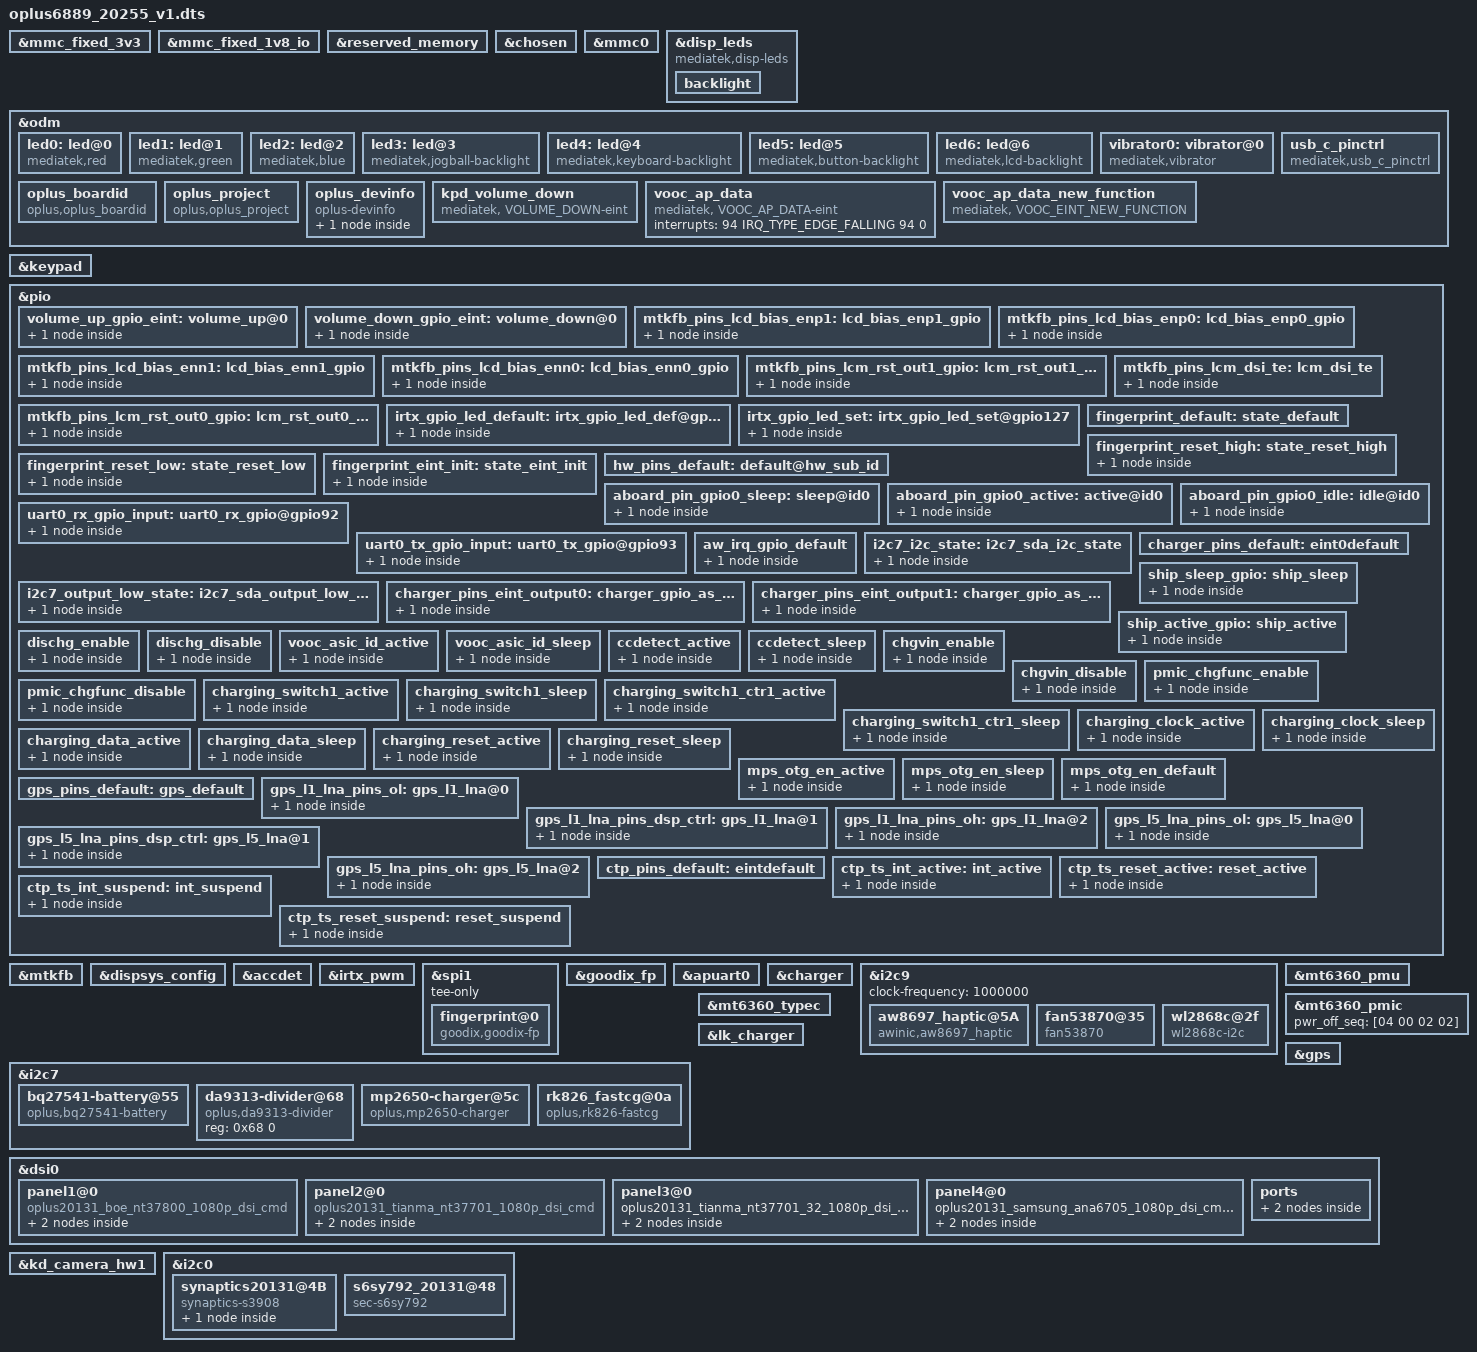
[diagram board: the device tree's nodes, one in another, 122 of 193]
// SPDX-License-Identifier: GPL-2.0
/*
 * Copyright (c) 2019 MediaTek Inc.
 *
 */
/dts-v1/;
/plugin/;
#include <dt-bindings/interrupt-controller/irq.h>
#include <dt-bindings/interrupt-controller/arm-gic.h>
#include <dt-bindings/spmi/spmi.h>
#include <dt-bindings/pinctrl/mt6885-pinfunc.h>

&mmc_fixed_3v3 {
	status = "okay";
	regulator-name = "mmc_power";
	regulator-min-microvolt = <3300000>;
	regulator-max-microvolt = <3300000>;
	enable-active-high;
	regulator-always-on;
};

&mmc_fixed_1v8_io {
	status = "okay";
	regulator-name = "mmc_io";
	regulator-min-microvolt = <1800000>;
	regulator-max-microvolt = <1800000>;
	enable-active-high;
	regulator-always-on;
};

&reserved_memory {
};

/* chosen */
&chosen {

	atag,videolfb-fb_base_l = <0x7e020000>;
	atag,videolfb-fb_base_h = <0x0>;
	atag,videolfb-islcmfound = <1>;
	atag,videolfb-islcm_inited = <0>;
	atag,videolfb-fps= <6000>;
	atag,videolfb-vramSize= <0x1be0000>;
	atag,videolfb-lcmname=
		"nt35595_fhd_dsi_cmd_truly_nt50358_drv";
};

&mmc0 {
	status = "okay";
	/* pinctrl-names = "default", "state_uhs"; */
	/* pinctrl-0 = <&mmc0_pins_default>; */
	/* pinctrl-1 = <&mmc0_pins_uhs>; */
	bus-width = <8>;
	max-frequency = <5000000>;
	cap-mmc-highspeed;
	no-sdio;
	no-sd;
	vmmc-supply = <&mmc_fixed_3v3>;
	vqmmc-supply = <&mmc_fixed_1v8_io>;
	non-removable;
};

&disp_leds {
	compatible = "mediatek,disp-leds";
	backlight {
		label = "lcd-backlight";
		max-brightness = <4095>;
		led-bits = <12>;
		trans-bits = <12>;
		default-state = "on";
	};
};

&odm {
	led0:led@0 {
		compatible = "mediatek,red";
		led_mode = <0>;
		data = <1>;
		pwm_config = <0 0 0 0 0>;
	};
	led1:led@1 {
		compatible = "mediatek,green";
		led_mode = <0>;
		data = <1>;
		pwm_config = <0 0 0 0 0>;
	};
	led2:led@2 {
		compatible = "mediatek,blue";
		led_mode = <0>;
		data = <1>;
		pwm_config = <0 0 0 0 0>;
	};
	led3:led@3 {
		compatible = "mediatek,jogball-backlight";
		led_mode = <0>;
		data = <1>;
		pwm_config = <0 0 0 0 0>;
	};
	led4:led@4 {
		compatible = "mediatek,keyboard-backlight";
		led_mode = <0>;
		data = <1>;
		pwm_config = <0 0 0 0 0>;
	};
	led5:led@5 {
		compatible = "mediatek,button-backlight";
		led_mode = <0>;
		data = <1>;
		pwm_config = <0 0 0 0 0>;
	};
	led6:led@6 {
		compatible = "mediatek,lcd-backlight";
		led_mode = <0>;
		data = <1>;
		pwm_config = <0 1 0 0 0>;
	};
	vibrator0:vibrator@0 {
		compatible = "mediatek,vibrator";
		vib_timer = <25>;
		vib_limit = <9>;
		vib_vol= <9>;
	};
	usb_c_pinctrl:usb_c_pinctrl {
		compatible = "mediatek,usb_c_pinctrl";
	};

	oplus_boardid:oplus_boardid {
		compatible = "oplus,oplus_boardid";
		oplus_boardid,dtsino="20255";//only one u32
		oplus_boardid,pcbmask="0x0004";//all mask 0xffff
	};

/*OPLUS_FEATURE_TP_BASIC oplus project start */
	oplus_project:oplus_project {
		compatible = "oplus,oplus_project";
	};
	oplus_devinfo:oplus_devinfo {
		compatible = "oplus-devinfo";
		pinctrl-names = "default", "aboard_gpio0_sleep", "aboard_gpio0_active", "aboard_gpio0_idle";
		pinctrl-0 = <&hw_pins_default>;
		pinctrl-1 = <&aboard_pin_gpio0_sleep>;
		pinctrl-2 = <&aboard_pin_gpio0_active>;
		pinctrl-3 = <&aboard_pin_gpio0_idle>;
		main-sub {
			use_tristate_gpio;
			compatible = "hw-match, main-sub";
			aboard-gpio0 = <&pio 132 0x00>;
			aboard-patterns = <1 1>;	/*0[high-resistance] 1[pull-down] 2[pull-up]*/
			/*main board*/
			match-projects = <20255 20257>;
		};
	};
/*OPLUS_FEATURE_TP_BASIC oplus project end */

//#ifdef OPLUS_FEATURE_TP_BASIC
        kpd_volume_down:kpd_volume_down {
                compatible = "mediatek, VOLUME_DOWN-eint";
                interrupt-parent = <&pio>;
                interrupts = <155 IRQ_TYPE_EDGE_FALLING 155 0>;
                debounce = <32000>;
                status = "okay";
        };
//#endif OPLUS_FEATURE_TP_BASIC

};
//#ifdef OPLUS_FEATURE_TP_BASIC
&keypad {
        keypad,volume-up        = <&pio 20 0x00>;
        keypad,volume-down      = <&pio 155 0x00>;
        pinctrl-names = "volume_up_as_int", "volume_down_as_int";
        pinctrl-0 = <&volume_up_gpio_eint>;
        pinctrl-1 = <&volume_down_gpio_eint>;
        status = "okay";
};

&pio {
        volume_up_gpio_eint:volume_up@0{
                pins_cmd_dat {
                        pinmux = <PINMUX_GPIO59__FUNC_GPIO59>;
                        slew-rate = <0>;  /*direction 0:in, 1:out*/
                        input-enable;
                };
        };

        volume_down_gpio_eint:volume_down@0{
                pins_cmd_dat {
                        pinmux = <PINMUX_GPIO155__FUNC_GPIO155>;
                        slew-rate = <0>;  /*direction 0:in, 1:out*/
                        input-enable;
                };
        };
};
//#endif OPLUS_FEATURE_TP_BASIC

/* DISPSYS GPIO standardization */
&pio {
	mtkfb_pins_lcd_bias_enp1: lcd_bias_enp1_gpio {
		pins_cmd_dat {
			pinmux = <PINMUX_GPIO28__FUNC_GPIO28>;
			slew-rate = <1>;
			output-high;
		};
	};

	mtkfb_pins_lcd_bias_enp0: lcd_bias_enp0_gpio {
		pins_cmd_dat {
			pinmux = <PINMUX_GPIO28__FUNC_GPIO28>;
			slew-rate = <1>;
			output-low;
		};
	};

	mtkfb_pins_lcd_bias_enn1: lcd_bias_enn1_gpio {
		pins_cmd_dat {
			pinmux = <PINMUX_GPIO29__FUNC_GPIO29>;
			slew-rate = <1>;
			output-high;
		};
	};

	mtkfb_pins_lcd_bias_enn0: lcd_bias_enn0_gpio {
		pins_cmd_dat {
			pinmux = <PINMUX_GPIO29__FUNC_GPIO29>;
			slew-rate = <1>;
			output-low;
		};
	};

	mtkfb_pins_lcm_rst_out1_gpio: lcm_rst_out1_gpio {
		pins_cmd_dat {
			pinmux = <PINMUX_GPIO42__FUNC_GPIO42>;
			slew-rate = <1>;
			output-high;
		};
	};

	mtkfb_pins_lcm_rst_out0_gpio: lcm_rst_out0_gpio {
		pins_cmd_dat {
			pinmux = <PINMUX_GPIO42__FUNC_GPIO42>;
			slew-rate = <1>;
			output-low;
		};
	};

	mtkfb_pins_lcm_dsi_te: lcm_dsi_te {
		pins_cmd_dat {
			pinmux = <PINMUX_GPIO41__FUNC_DSI_TE>;
		};
	};
};

&mtkfb {
	pinctrl-names = "lcd_bias_enp1_gpio", "lcd_bias_enp0_gpio",
		"lcd_bias_enn1_gpio", "lcd_bias_enn0_gpio",
		"lcm_rst_out1_gpio", "lcm_rst_out0_gpio",
		"mode_te_te";
	pinctrl-0 = <&mtkfb_pins_lcd_bias_enp1>;
	pinctrl-1 = <&mtkfb_pins_lcd_bias_enp0>;
	pinctrl-2 = <&mtkfb_pins_lcd_bias_enn1>;
	pinctrl-3 = <&mtkfb_pins_lcd_bias_enn0>;
	pinctrl-4 = <&mtkfb_pins_lcm_rst_out1_gpio>;
	pinctrl-5 = <&mtkfb_pins_lcm_rst_out0_gpio>;
	pinctrl-6 = <&mtkfb_pins_lcm_dsi_te>;
	status = "okay";
};

&dispsys_config {
	pinctrl-names =
		"lcm_rst_out1_gpio", "lcm_rst_out0_gpio",
		"mode_te_te";
	pinctrl-0 = <&mtkfb_pins_lcm_rst_out1_gpio>;
	pinctrl-1 = <&mtkfb_pins_lcm_rst_out0_gpio>;
	pinctrl-2 = <&mtkfb_pins_lcm_dsi_te>;
	status = "okay";

	helper-value = <0>, /*MTK_DRM_OPT_STAGE*/
		<1>, /*MTK_DRM_OPT_USE_CMDQ*/
		<1>, /*MTK_DRM_OPT_USE_M4U*/
		<0>, /*MTK_DRM_OPT_SODI_SUPPORT*/
		<1>, /*MTK_DRM_OPT_IDLE_MGR*/
		<0>, /*MTK_DRM_OPT_IDLEMGR_SWTCH_DECOUPLE*/
		<1>, /*MTK_DRM_OPT_IDLEMGR_BY_REPAINT*/
		<0>, /*MTK_DRM_OPT_IDLEMGR_ENTER_ULPS*/
		<0>, /*MTK_DRM_OPT_IDLEMGR_KEEP_LP11*/
		<0>, /*MTK_DRM_OPT_DYNAMIC_RDMA_GOLDEN_SETTING*/
		<1>, /*MTK_DRM_OPT_IDLEMGR_DISABLE_ROUTINE_IRQ*/
		<0>, /*MTK_DRM_OPT_MET_LOG*/
		<1>, /*MTK_DRM_OPT_USE_PQ*/
		<1>, /*MTK_DRM_OPT_ESD_CHECK_RECOVERY*/
		<1>, /*MTK_DRM_OPT_ESD_CHECK_SWITCH*/
		<1>, /*MTK_DRM_OPT_PRESENT_FENCE*/
		<0>, /*MTK_DRM_OPT_RDMA_UNDERFLOW_AEE*/
		<0>, /*MTK_DRM_OPT_DSI_UNDERRUN_AEE*/
		<1>, /*MTK_DRM_OPT_HRT*/
		<1>, /*MTK_DRM_OPT_HRT_MODE*/
		<0>, /*MTK_DRM_OPT_DELAYED_TRIGGER*/
		<1>, /*MTK_DRM_OPT_OVL_EXT_LAYER*/
		<0>, /*MTK_DRM_OPT_AOD*/
		<1>, /*MTK_DRM_OPT_RPO*/
		<0>, /*MTK_DRM_OPT_DUAL_PIPE*/
		<0>, /*MTK_DRM_OPT_DC_BY_HRT*/
		<1>, /*MTK_DRM_OPT_OVL_WCG*/
		<0>, /*MTK_DRM_OPT_OVL_SBCH*/
		<1>, /*MTK_DRM_OPT_COMMIT_NO_WAIT_VBLANK*/
		<0>, /*MTK_DRM_OPT_MET*/
		<0>, /*MTK_DRM_OPT_REG_PARSER_RAW_DUMP*/
		<0>, /*MTK_DRM_OPT_VP_PQ*/
		<0>, /*MTK_DRM_OPT_GAME_PQ*/
		<0>, /*MTK_DRM_OPT_MMPATH*/
		<1>, /*MTK_DRM_OPT_HBM*/
		<0>, /*MTK_DRM_OPT_VDS_PATH_SWITCH*/
		<0>, /*MTK_DRM_OPT_LAYER_REC*/
		<1>, /*MTK_DRM_OPT_CLEAR_LAYER*/
		<0>, /*MTK_DRM_OPT_SF_PF*/
		<1>, /*MTK_DRM_OPT_PRIM_DUAL_PIPE*/
		<1>; /*MTK_DRM_OPT_DYN_MIPI_CHANGE*/
};
/* DISPSYS GPIO standardization end */

/* accdet start */
&accdet {
	/* accdet micbias voltage: 0x09:2.85v 0x08:2.8v 0x07,
	 * 2.7v;0x05,2.5v;0x02,1.9v
	 */
	accdet-mic-vol = <8>;
	/* accdet pwm_width, pwm_thresh, fall_delay, rise_delay
	 * debounce0, debounce1, debounce3, debounce4
	 * eint pwm_width, eint pwm_thresh
	 * eint deb(debounce0, debounce1, debounce2, debounce3), inv_debounce
	 */
	headset-mode-setting = <0x500 0x500 1 0x1f0
				0x800 0x800 0x20 0x44
				0x4 0x1
				0x5 0x3 0x3 0x5 0xe>;
	accdet-plugout-debounce = <1>;
	/*1:ACC mode, 2:low cost without in bias, 6:low cost with in bias*/
	accdet-mic-mode = <2>;
	/*0--MD_MAX--UP_MAX--DW_MAX*/
	headset-three-key-threshold = <0 80 220 400>;
	headset-three-key-threshold-CDD = <0 121 192 600>;
	/*0--MD_MAX--VOICE_MAX--UP_MAX--DW_MAX*/
	headset-four-key-threshold = <0 58 121 192 400>;

	/* select VTH to 2v and 500k, use internal resitance */
	eint_use_ext_res = <0>;
	status = "okay";
};
/* accdet end */

/* IRTX GPIO Start */
&irtx_pwm {
	pinctrl-names = "irtx_gpio_led_default", "irtx_gpio_led_set";
	pinctrl-0 = <&irtx_gpio_led_default>;
	pinctrl-1 = <&irtx_gpio_led_set>;
	status = "okay";
};
&pio {
	/* IRTX GPIO Settings -Start */
	/* default: GPIO0, output, high */
	irtx_gpio_led_default:irtx_gpio_led_def@gpio127 {
		pins_cmd_dat {
			pinmux = <PINMUX_GPIO127__FUNC_GPIO127>;
			slew-rate = <1>;
			bias-disable;
			output-low;
			input-schmitt-enable = <0>;
		};
	};

	irtx_gpio_led_set:irtx_gpio_led_set@gpio127 {
		pins_cmd_dat {
			pinmux = <PINMUX_GPIO127__FUNC_PWM_3>;
			slew-rate = <1>;
			output-high;
		};
	};
}; /* IRTX GPIO Settings -End */

/* FINGERPRINT start */
&spi1 {
	#address-cells = <1>;
	#size-cells = <0>;
	tee-only;
	fingerprint@0 {
		compatible = "goodix,goodix-fp";
		reg = <0>;
		spi-max-frequency = <8000000>;
		netlink-event = <30>;
		vfp-supply = <&mt_pmic_vfp_ldo_reg>;
		power-type = <1>;
		status = "okay";
	};
};

&goodix_fp {
	pinctrl-names = "default", "reset_high", "reset_low", "eint_init";
	pinctrl-0 = <&fingerprint_default>;
	pinctrl-1 = <&fingerprint_reset_high>;
	pinctrl-2 = <&fingerprint_reset_low>;
	pinctrl-3 = <&fingerprint_eint_init>;
	interrupt-parent = <&pio>;
	interrupts = <15 IRQ_TYPE_EDGE_RISING 15 0>;
	status = "okay";
};

&pio {
	fingerprint_default: state_default {
	};
	fingerprint_reset_high: state_reset_high {
		pins_cmd_dat {
			pinmux = <PINMUX_GPIO14__FUNC_GPIO14>;
			slew-rate = <1>;
			output-high;
		};
	};
	fingerprint_reset_low: state_reset_low {
		pins_cmd_dat {
			pinmux = <PINMUX_GPIO14__FUNC_GPIO14>;
			slew-rate = <1>;
			output-low;
		};
	};
	fingerprint_eint_init: state_eint_init {
		pins_cmd_dat {
			pinmux = <PINMUX_GPIO15__FUNC_GPIO15>;
			slew-rate = <0>;
			bias-pull-up = <MTK_PUPD_SET_R1R0_10>;
			input-schmitt-enable;
		};
	};
};
/* FINGERPRINT end */
&pio {
    hw_pins_default:default@hw_sub_id {
    };

    aboard_pin_gpio0_sleep:sleep@id0 {
        pins_cmd_dat {
            pinmux = <PINMUX_GPIO132__FUNC_GPIO132>;
            slew-rate = <0>;
            bias-pull-down;
            input-enable;
        };
    };

    aboard_pin_gpio0_active:active@id0 {
        pins_cmd_dat {
            pinmux = <PINMUX_GPIO132__FUNC_GPIO132>;
            slew-rate = <0>;
            bias-pull-up;
            input-enable;
        };
    };

    aboard_pin_gpio0_idle:idle@id0 {
        pins_cmd_dat {
            pinmux = <PINMUX_GPIO132__FUNC_GPIO132>;
            slew-rate = <0>;
            bias-disable;
            input-enable;
        };
    };
};

&apuart0 {
	pinctrl-names = "uart0_rx_gpio","uart0_tx_gpio";
	pinctrl-0 = <&uart0_rx_gpio_input>;
	pinctrl-1 = <&uart0_tx_gpio_input>;
	status = "okay";
};

&pio {
	uart0_rx_gpio_input:uart0_rx_gpio@gpio92 {
		pins_cmd_dat {
			pinmux = <PINMUX_GPIO92__FUNC_GPIO92>;
			input-enable;
			slew-rate = <0>;
			bias-disable;
		};
	};
	uart0_tx_gpio_input:uart0_tx_gpio@gpio93 {
		pins_cmd_dat {
			pinmux = <PINMUX_GPIO93__FUNC_GPIO93>;
			input-enable;
			slew-rate = <0>;
			bias-disable;
		};
	};
};

/* 2020/07/30, zdr Add for oplus charge .*/
&charger {
	io-channels = <&auxadc 4>,
		<&auxadc 5>;
	io-channel-names = "auxadc4-usb_temp_v_l",
		"auxadc5-usb_temp_v_r";

	pinctrl-names = "default", "charger_gpio_as_output_low", "charger_gpio_as_output_high", "ship_sleep", "ship_active",
		"dischg_enable", "dischg_disable", "chgvin_enable", "chgvin_disable", "pmic_chgfunc_enable", "pmic_chgfunc_disable",
		"ccdetect_active","ccdetect_sleep";
	pinctrl-0 = <&charger_pins_default>;
	pinctrl-1 = <&charger_pins_eint_output0>;	//USB_ON -> USB_SWITCH:(UART && USB)
	pinctrl-2 = <&charger_pins_eint_output1>;
	pinctrl-3 = <&ship_sleep_gpio>;				//ship_mode
	pinctrl-4 = <&ship_active_gpio>;
	pinctrl-5 = <&dischg_enable>;				//usb_hightemp_port
	pinctrl-6 = <&dischg_disable>;
	pinctrl-7 = <&chgvin_enable>;					//EVB GPIO30 chgvin
	pinctrl-8 = <&chgvin_disable>;
	pinctrl-9 = <&pmic_chgfunc_enable>;				//EVB GPIO26 chg_enable
	pinctrl-10 = <&pmic_chgfunc_disable>;
	//pinctrl-5 = <&shortc_active_gpio>;
	pinctrl-11 = <&ccdetect_active>;
	pinctrl-12 = <&ccdetect_sleep>;
	qcom,hv_flashled_support;
	qcom,chargerid_support;
	qcom,smart_charging_screenoff;
	qcom,usbtemp_batttemp_gap = <18>;
	qcom,input_current_charger_ma = <2000>;
	qcom,pd_input_current_charger_ma = <2000>;
	qcom,qc_input_current_charger_ma = <2000>;
	qcom,input_current_usb_ma = <500>;

	qcom,input_current_led_ma = <1200>;
	qcom,input_current_led_ma_high = <1200>;
	qcom,input_current_led_ma_warm = <1500>;
	qcom,input_current_led_ma_normal = <2000>;
	qcom,led_warm_bat_decidegc = <350>;
	qcom,led_high_bat_decidegc = <370>;

	qcom,input_current_camera_ma = <1200>;
	qcom,input_current_cdp_ma = <1500>;

	qcom,input_current_vooc_led_ma_high = <1200>;
	qcom,input_current_vooc_led_ma_warm = <1800>;
	qcom,input_current_vooc_led_ma_normal = <3600>;
	qcom,input_current_vooc_ma_normal = <3600>;
	qcom,vooc_temp_bat_normal_decidegc = <350>;
	qcom,input_current_vooc_ma_warm = <3200>;
	qcom,vooc_temp_bat_warm_decidegc = <370>;
	qcom,input_current_vooc_ma_high = <2200>;
	qcom,vooc_temp_bat_hot_decidegc = <440>;

	qcom,charger_current_vooc_ma_normal = <1800>;

	qcom,chg_ctrl_by_calling;
	qcom,input_current_calling_ma = <1500>;

	qcom,overtemp_bat_decidegc = <350>;
	qcom,iterm_disabled = <0>;
	sw_full_count = <25>;
	qcom,iterm_ma = <118>;
	qcom,recharge-mv = <100>;
	qcom,batt_capacity_mah = <4250>;/*typical capacity*/

	qcom,removed_bat_decidegc = <190>;  /*<-19C*/

	qcom,cold_bat_decidegc = <20>;  /*-2C~0C*/
	qcom,temp_cold_vfloat_mv = <3980>;
	qcom,temp_cold_fastchg_current_ma = <300>;

	qcom,little_cold_bat_decidegc = <0>;    /*0C~5C*/
	qcom,temp_little_cold_vfloat_mv = <4435>;
	qcom,temp_little_cold_fastchg_current_ma_high = <1100>;
	qcom,temp_little_cold_fastchg_current_ma_low = <1100>;
	qcom,temp_little_cold_fastchg_current_ma = <920>;
	qcom,pd_temp_little_cold_fastchg_current_ma_high = <2000>;
	qcom,pd_temp_little_cold_fastchg_current_ma_low = <1400>;
	qcom,qc_temp_little_cold_fastchg_current_ma_high = <2000>;
	qcom,qc_temp_little_cold_fastchg_current_ma_low = <1400>;

	qcom,cool_bat_decidegc = <50>;  /*5C~12C*/
	qcom,temp_cool_vfloat_mv = <4435>;
	qcom,temp_cool_fastchg_current_ma_high = <1100>;
	qcom,temp_cool_fastchg_current_ma_low = <1100>;
	qcom,pd_temp_cool_fastchg_current_ma_high = <2000>;
	qcom,pd_temp_cool_fastchg_current_ma_low = <2000>;
	qcom,qc_temp_cool_fastchg_current_ma_high = <2000>;
	qcom,qc_temp_cool_fastchg_current_ma_low = <2000>;

	qcom,little_cool_bat_decidegc = <120>;  /*12C~16C*/
	qcom,temp_little_cool_vfloat_mv = <4435>;
	qcom,temp_little_cool_fastchg_current_ma = <1100>;
	qcom,pd_temp_little_cool_fastchg_current_ma = <2000>;
	qcom,qc_temp_little_cool_fastchg_current_ma = <2000>;

	qcom,normal_bat_decidegc = <160>;       /*16C~44C*/
	qcom,temp_normal_fastchg_current_ma = <2000>;
	qcom,temp_normal_vfloat_mv = <4435>;
	qcom,pd_temp_normal_fastchg_current_ma = <2000>;
	qcom,qc_temp_normal_fastchg_current_ma = <2000>;

	qcom,warm_bat_decidegc = <450>;         /*45C~53C*/ /*8pin Bat Vooc project need add 3 degree C*/
	qcom,temp_warm_vfloat_mv = <4130>;
	qcom,temp_warm_fastchg_current_ma = <600>;
	qcom,pd_temp_warm_fastchg_current_ma = <600>;
	qcom,qc_temp_warm_fastchg_current_ma = <600>;
	qcom,temp_warm_fastchg_current_ma_led_on = <250>;

	qcom,hot_bat_decidegc = <530>;

	qcom,non_standard_vfloat_mv = <3980>;
	qcom,non_standard_fastchg_current_ma = <512>;

	qcom,short_c_bat_cv_mv = <4330>;
	qcom,short_c_bat_vfloat_mv = <3800>;
	qcom,short_c_bat_fastchg_current_ma = <512>;

	qcom,cold_vfloat_sw_limit = <3930>;
	qcom,little_cold_vfloat_sw_limit = <4385>;
	qcom,cool_vfloat_sw_limit = <4385>;
	qcom,little_cool_vfloat_sw_limit = <4385>;
	qcom,normal_vfloat_sw_limit = <4385>;
	qcom,warm_vfloat_sw_limit = <4080>;
	qcom,non_standard_vfloat_sw_limit = <3930>;
	qcom,short_c_bat_vfloat_sw_limit = <3750>;

	qcom,max_chg_time_sec = <60480>;
	qcom,charger_hv_thr = <9900>;
	qcom,charger_recv_thr = <9500>;
	qcom,charger_lv_thr = <3400>;
	qcom,vbatt_full_thr = <4435>;
	qcom,vbatt_hv_thr = <4600>;
	qcom,vfloat_step_mv = <8>;
	qcom,non_standard_vfloat_over_sw_limit = <3990>;
	qcom,cold_vfloat_over_sw_limit = <3990>;
	qcom,little_cold_vfloat_over_sw_limit = <4445>;
	qcom,cool_vfloat_over_sw_limit = <4445>;
	qcom,little_cool_vfloat_over_sw_limit = <4445>;
	qcom,normal_vfloat_over_sw_limit = <4445>;
	qcom,warm_vfloat_over_sw_limit = <4140>;

	qcom,vbatt_power_off = <3300>;
	qcom,vbatt_soc_1 = <3310>;
	qcom,vooc_project = <3>;
	qcom,vbatt_num = <2>;
	qcom,new_ui_warning_support;
	qcom,ffc_support;
	qcom,dual_ffc;
	recharge_after_full;

	qcom,normal_vterm_hw_inc = <18>;
	qcom,non_normal_vterm_hw_inc = <18>;

	qcom,ff1_normal_fastchg_ma = <550>;
	qcom,ff1_warm_fastchg_ma = <550>;

	qcom,ffc2_normal_fastchg_ma = <350>;/*12C~35c*/
	qcom,ffc2_temp_warm_decidegc = <350>;
	qcom,ffc2_warm_fastchg_ma = <350>;/*35C~40c*/
	qcom,ffc2_temp_high_decidegc = <400>;
	qcom,ffc2_temp_low_decidegc = <120>;

	qcom,ff1_exit_step_ma = <150>;
	qcom,ff1_warm_exit_step_ma = <150>;
	qcom,ffc2_exit_step_ma = <150>;
	qcom,ffc2_warm_exit_step_ma = <150>;

	qcom,ffc_normal_vfloat_sw_limit = <4455>;
	qcom,ffc_temp_normal_vfloat_mv = <4500>;
	qcom,ffc_normal_vfloat_over_sw_limit = <4500>;
	qcom,ffc_warm_vfloat_sw_limit = <4450>;
	qcom,ffc_temp_warm_vfloat_mv = <4500>;
	qcom,ffc_warm_vfloat_over_sw_limit = <4500>;

	qcom,ffc2_normal_vfloat_sw_limit = <4445>;
	qcom,ffc2_temp_normal_vfloat_mv = <4500>;
	qcom,ffc2_normal_vfloat_over_sw_limit = <4500>;
	qcom,ffc2_warm_vfloat_sw_limit = <4440>;
	qcom,ffc2_temp_warm_vfloat_mv = <4500>;
	qcom,ffc2_warm_vfloat_over_sw_limit = <4500>;

	qcom,default_iterm_ma = <118>;
	qcom,default_temp_normal_fastchg_current_ma = <1000>;
	qcom,default_normal_vfloat_sw_limit = <4385>;
	qcom,default_temp_normal_vfloat_mv = <4435>;
	qcom,default_normal_vfloat_over_sw_limit = <4445>;

	qcom,default_temp_little_cool_fastchg_current_ma = <1100>;
	qcom,default_little_cool_vfloat_sw_limit = <4385>;
	qcom,default_temp_little_cool_vfloat_mv = <4435>;
	qcom,default_little_cool_vfloat_over_sw_limit = <4445>;

	qcom,vooc_show_ui_soc_decimal;
	qcom,ui_soc_decimal_speedmin = <20>;//2A
	qcom,check_batt_full_by_sw;
	qcom,external_gauge;
	qcom,chg_ctrl_by_lcd;
	qcom,chg_ctrl_by_vooc;
	qcom,chg_ctrl_by_camera;
	qcom,support_ntc_01c_precision;
	qcom,sw_vfloat_over_protect_enable;

	//for PD9V or QC9V
	qcom,vbatt_pdqc_to_5v_thr = <4100>;
	qcom,vbatt_pdqc_to_9v_thr = <4000>;

	//GPIO config:
	qcom,chargerid_switch-gpio = <&pio 192 0x00>;	//check
	qcom,ship-gpio = <&pio 126 0x00>;		//check
	qcom,dischg-gpio = <&pio 51 0x00>;		//check
	//qcom,shortc-gpio = <&pio 121 0x00>;
	qcom,ccdetect-gpio = <&pio 5 0x00>;

	//Lukaili Add for camera flash led
	qcom,chgvin = <&pio 30 0x00>;		//check
	qcom,pmic_chgfunc = <&pio 26 0x00>;		//check
};

&i2c9 {
    status = "okay";
	clock-frequency = <1000000>;

	/* AWINIC AW8697 Haptic */
	aw8697_haptic@5A {
		status = "okay";
		compatible = "awinic,aw8697_haptic";
		reg = <0x5A>;
		reset-gpio = <&pio 110 0x00>;
		irq-gpio = <&pio 8 0x00>;
		qcom,device_id = <832>;//19065

		pinctrl-names = "default";
		pinctrl-0 = <&aw_irq_gpio_default>;
	};
};

&pio{
	aw_irq_gpio_default: aw_irq_gpio_default {		//check
		pins_cmd_dat {
			pinmux = <PINMUX_GPIO8__FUNC_GPIO8>;
			input-enable;
			slew-rate = <0>;
			bias-pull-up;
		};
	};

};

&odm {
	vooc_ap_data:vooc_ap_data {
		compatible = "mediatek, VOOC_AP_DATA-eint";
		interrupts = <94 IRQ_TYPE_EDGE_FALLING 94 0>;
	};
	vooc_ap_data_new_function:vooc_ap_data_new_function {
		compatible = "mediatek, VOOC_EINT_NEW_FUNCTION";
	};
};

&i2c7 {
       pinctrl-names = "i2c-state", "output-low-state";

       pinctrl-0 = <&i2c7_i2c_state>;
       pinctrl-1 = <&i2c7_output_low_state>;
};
&pio {
       i2c7_i2c_state: i2c7_sda_i2c_state {
                pins_cmd_dat {
                          pinmux = <PINMUX_GPIO125__FUNC_SDA7>;
                          slew-rate = <0>;
                          bias-disable;
                };
       };
       i2c7_output_low_state: i2c7_sda_output_low_state {
                pins_cmd_dat {
                          pinmux = <PINMUX_GPIO125__FUNC_GPIO125>;
                          slew-rate = <1>;
                          output-low;
                };
       };
};


&i2c7 {
	status = "okay";
	clock-frequency = <100000>;

	bq27541-battery@55 {
		status = "okay";
		compatible = "oplus,bq27541-battery";
		reg = <0x55 0>;
		qcom,modify-soc-smooth;
		qcom,modify-soc-calibration;
		qcom,batt_bq28z610 = <1>;
		qcom,sha1_key_index = <1>;
        //qcom,bq28z610_need_balancing;
	};

	da9313-divider@68 {
		status = "okay";
		compatible = "oplus,da9313-divider";
		reg = <0x68 0>;
	};

	mp2650-charger@5c {
		status = "okay";
		compatible = "oplus,mp2650-charger";
		reg = <0x5c 0>;

		qcom,mps_otg_en-gpio = <&pio 129 0x00>;		//check
		pinctrl-names = "mps_otg_en_active", "mps_otg_en_sleep", "mps_otg_en_default";
		pinctrl-0 = <&mps_otg_en_active>;
		pinctrl-1 = <&mps_otg_en_sleep>;
		pinctrl-2 = <&mps_otg_en_default>;
	};

	rk826_fastcg@0a{
		status = "okay";
		compatible = "oplus,rk826-fastcg";
		reg = <0x0a 0>;
		qcom,oplus_batt_4400mv;
		qcom,support_vooc_by_normal_charger_path;
		qcom,vooc_fw_update_newmethod;
		qcom,vooc-fw-type = <3>;
		qcom,vooc_reply_mcu_bits = <7>;
		qcom,vooc-low-temp = <0>;
		qcom,vooc-high-temp = <430>;
		qcom,vooc-low-soc = <1>;
		qcom,vooc-high-soc = <90>;
		qcom,vooc-max-input-volt-support = <10000>;     //10V
		qcom,vooc-max-input-current-support = <6500>;   //6.5A
		qcom,vooc-little-cool-temp = <160>;
		qcom,vooc-cool-temp = <120>;
		qcom,vooc-little-cool-to-normal-temp = <180>;
		qcom,vooc-normal-to-little-cool-current = <0x05>;//5A

		qcom,vooc_multistep_adjust_current_support;
		qcom,vooc_multistep_initial_batt_temp = <1000>;
		qcom,vooc_strategy_normal_current = <0x0c>;
		qcom,vooc_batt_over_high_temp = <440>;
		qcom,vooc_batt_over_low_temp = <45>;
		qcom,vooc_over_high_or_low_current = <0x0>;

		qcom,vooc_strategy1_batt_high_temp0 = <400>;
		qcom,vooc_strategy1_batt_high_temp1 = <420>;
		qcom,vooc_strategy1_batt_high_temp2 = <430>;
		qcom,vooc_strategy1_batt_low_temp2 = <420>;
		qcom,vooc_strategy1_batt_low_temp1 = <410>;
		qcom,vooc_strategy1_batt_low_temp0 = <390>;

		qcom,vooc_strategy1_high_current0 = <0x09>;  //5A
		qcom,vooc_strategy1_high_current1 = <0x07>;  // 4A
		qcom,vooc_strategy1_high_current2 = <0x05>;  // 3A
		qcom,vooc_strategy1_low_current2 = <0x07>;   // 4A
		qcom,vooc_strategy1_low_current1 = <0x09>;   // 5A
		qcom,vooc_strategy1_low_current0 = <0x0c>;   // 0x0c

		qcom,vooc_strategy2_batt_up_temp1 = <375>;
		qcom,vooc_strategy2_batt_up_down_temp2 = <380>;
		qcom,vooc_strategy2_batt_up_temp3 = <390>;
		qcom,vooc_strategy2_batt_up_down_temp4 = <400>;
		qcom,vooc_strategy2_batt_up_temp5 = <410>;
		qcom,vooc_strategy2_batt_up_temp6 = <415>;
		qcom,vooc_strategy2_high0_current = <0x09>;
		qcom,vooc_strategy2_high1_current = <0x07>;
		qcom,vooc_strategy2_high2_current = <0x05>;
		qcom,vooc_strategy2_high3_current = <0x03>;

		qcom,vooc_current_lvl = <1000
									1500
									2000
									2500
									3000
									3500
									4000
									4500
									5000
									5500
									6000
									6500
									7000
									7500
									8000
									8500
									9000
									9500
									10000
									10500
									11000
									11500
									12000
									12500>;
		pinctrl-names = "switch1_act_switch2_act", "switch1_sleep_switch2_sleep",
						"switch1_act_switch3_act", "switch1_sleep_switch3_sleep",
						"switch1_act_switch2_sleep", "switch1_sleep_switch2_act",
						"clock_active","clock_sleep",
						"data_active","data_sleep",
						"reset_active","reset_sleep",
						"charging_switch1_ctr1_active","charging_switch1_ctr1_sleep",
						"vooc_asic_id_active","vooc_asic_id_sleep";
		pinctrl-0 = <&charging_switch1_active>;
		pinctrl-1 = <&charging_switch1_sleep>;
		pinctrl-2 = <&charging_switch1_active>;
		pinctrl-3 = <&charging_switch1_sleep>;
		pinctrl-4 = <&charging_switch1_active>;
		pinctrl-5 = <&charging_switch1_sleep>;
		pinctrl-6 = <&charging_clock_active>;
		pinctrl-7 = <&charging_clock_sleep>;
		pinctrl-8 = <&charging_data_active>;
		pinctrl-9 = <&charging_data_sleep>;
		pinctrl-10 = <&charging_reset_active>;
		pinctrl-11 = <&charging_reset_sleep>;
		pinctrl-12 = <&charging_switch1_ctr1_active>;
		pinctrl-13 = <&charging_switch1_ctr1_sleep>;
		pinctrl-14 = <&vooc_asic_id_active>;
		pinctrl-15 = <&vooc_asic_id_sleep>;

		qcom,charging_switch1-gpio 		= <&pio 191 0x00>;		//check
		qcom,charging_switch1_ctr1-gpio 	= <&pio 163 0x00>;	//empty
		//qcom,charging_switch2-gpio 		= <&tlmm 113 0x00>;
		//qcom,charging_switch3-gpio 		= <&tlmm 38 0x00>;

		qcom,charging_reset-gpio 			= <&pio 189 0x00>;		//check
		qcom,charging_clock-gpio 			= <&pio 95 0x00>;		//check
		qcom,charging_data-gpio 			= <&pio 94 0x00>;		//check
		qcom,vooc_asic_id-gpio				= <&pio 187 0x00>;
	};
};

&pio {
	charger_pins_default: eint0default {
	};

	charger_pins_eint_output0: charger_gpio_as_output_low {		//check
		pins_cmd_dat {
			pinmux = <PINMUX_GPIO192__FUNC_GPIO192>;
			slew-rate = <1>;
			output-low;
		};
	};

	charger_pins_eint_output1: charger_gpio_as_output_high {	//check
		pins_cmd_dat {
			pinmux = <PINMUX_GPIO192__FUNC_GPIO192>;
			slew-rate = <1>;
			output-high;
		};
	};

	ship_sleep_gpio: ship_sleep {
		pins_cmd_dat {
			pinmux = <PINMUX_GPIO126__FUNC_GPIO126>;		//check
			slew-rate = <1>;
			output-low;
		};
	};

	ship_active_gpio: ship_active {
		pins_cmd_dat {
			pinmux = <PINMUX_GPIO126__FUNC_GPIO126>;		//check
			slew-rate = <1>;
			output-high;
		};
	};

	dischg_enable: dischg_enable {
		pins_cmd_dat {
			pinmux = <PINMUX_GPIO51__FUNC_GPIO51>;		//check
			slew-rate = <1>;							//0:input direction 1:output direction
			bias-pull-up;
			output-high;
		};
	};

	dischg_disable: dischg_disable {
		pins_cmd_dat {
			pinmux = <PINMUX_GPIO51__FUNC_GPIO51>;		//check
			slew-rate = <1>;
			bias-pull-down = <00>;
			output-low;
		};
	};

	vooc_asic_id_active: vooc_asic_id_active {
		pins_cmd_dat {
			pinmux = <PINMUX_GPIO187__FUNC_GPIO187>;
			input-enable;
			slew-rate = <0>;
			bias-pull-up;
		};
	};

	vooc_asic_id_sleep: vooc_asic_id_sleep {
		pins_cmd_dat {
			pinmux = <PINMUX_GPIO187__FUNC_GPIO187>;
			input-enable;
			slew-rate = <0>;
			bias-pull-down;
		};
	};

	ccdetect_active: ccdetect_active {
		pins_cmd_dat {
			pinmux = <PINMUX_GPIO5__FUNC_GPIO5>;
			input-enable;
			slew-rate = <0>;
			bias-disable;
		};
	};
	ccdetect_sleep: ccdetect_sleep {
		pins_cmd_dat {
			pinmux = <PINMUX_GPIO5__FUNC_GPIO5>;
			input-enable;
			slew-rate = <0>;
			bias-disable;
		};
	};
	/*
	shortc_active_gpio: shortc_active {
		pins_cmd_dat {
			pinmux = <PINMUX_GPIO121__FUNC_GPIO121>;
			input-enable;
			slew-rate = <0>;
			bias-pull-up;
		};
	};*/

	//Lukaili Add for camera flash led
	chgvin_enable: chgvin_enable {
		pins_cmd_dat {
			pinmux = <PINMUX_GPIO30__FUNC_GPIO30>;				//check
			slew-rate = <1>;//0:input direction 1:output direction
			bias-pull-up;
			output-low;
		};
	};

	chgvin_disable: chgvin_disable {
		pins_cmd_dat {
			pinmux = <PINMUX_GPIO30__FUNC_GPIO30>;			//check
			slew-rate = <1>;
			bias-pull-down;
			output-high;
		};
	};

	pmic_chgfunc_enable: pmic_chgfunc_enable {
		pins_cmd_dat {
			pinmux = <PINMUX_GPIO26__FUNC_GPIO26>;			//check
			slew-rate = <1>;//0:input direction 1:output direction
			bias-pull-up;
			output-low;
		};
	};

	pmic_chgfunc_disable: pmic_chgfunc_disable {
		pins_cmd_dat {
			pinmux = <PINMUX_GPIO26__FUNC_GPIO26>;			//check
			slew-rate = <1>;
			bias-pull-down;
			output-high;
		};
	};
	//end Add for camera flash led
};

&pio {
	charging_switch1_active: charging_switch1_active {
		pins_cmd_dat {
			pinmux = <PINMUX_GPIO191__FUNC_GPIO191>;		//check
			slew-rate = <1>;
			output-high;
		};
	};

	charging_switch1_sleep: charging_switch1_sleep {
		pins_cmd_dat {
			pinmux = <PINMUX_GPIO191__FUNC_GPIO191>;		//check
			slew-rate = <1>;
			output-low;
		};
	};

	charging_switch1_ctr1_active: charging_switch1_ctr1_active {
		pins_cmd_dat {
			pinmux = <PINMUX_GPIO163__FUNC_GPIO163>;		//empty
			slew-rate = <1>;
			bias-pull-up;
		};
	};
	charging_switch1_ctr1_sleep: charging_switch1_ctr1_sleep {
		pins_cmd_dat {
			pinmux = <PINMUX_GPIO163__FUNC_GPIO163>;		//empty
			slew-rate = <1>;
			output-low;
		};
	};

	charging_clock_active: charging_clock_active {
		pins_cmd_dat {
			pinmux = <PINMUX_GPIO95__FUNC_GPIO95>;		//check
			slew-rate = <0>;
			bias-pull-up;
		};
	};

	charging_clock_sleep: charging_clock_sleep {
		pins_cmd_dat {
			pinmux = <PINMUX_GPIO95__FUNC_GPIO95>;		//check
			slew-rate = <0>;
			bias-pull-down;
		};
	};

	charging_data_active: charging_data_active {
		pins_cmd_dat {
			pinmux = <PINMUX_GPIO94__FUNC_GPIO94>;		//check
			slew-rate = <0>;
			bias-pull-down;
		};
	};

	charging_data_sleep: charging_data_sleep {
		pins_cmd_dat {
			pinmux = <PINMUX_GPIO94__FUNC_GPIO94>;		//check
			slew-rate = <0>;
			bias-pull-down;
		};
	};

	charging_reset_active: charging_reset_active {
		pins_cmd_dat {
			pinmux = <PINMUX_GPIO189__FUNC_GPIO189>;	//check
			slew-rate = <1>;
			bias-pull-down;
		};
	};

	charging_reset_sleep: charging_reset_sleep {
		pins_cmd_dat {
			pinmux = <PINMUX_GPIO189__FUNC_GPIO189>;	//check
			slew-rate = <1>;
			bias-pull-up;
		};
	};

	mps_otg_en_active: mps_otg_en_active {
		pins_cmd_dat {
			pinmux = <PINMUX_GPIO129__FUNC_GPIO129>;		//check
            slew-rate = <1>;
            bias-pull-up;
		};
	};

	mps_otg_en_sleep: mps_otg_en_sleep {
		pins_cmd_dat {
			pinmux = <PINMUX_GPIO129__FUNC_GPIO129>;		//check
			slew-rate = <1>;
			bias-pull-down;
		};
	};

	mps_otg_en_default: mps_otg_en_default {
		pins_cmd_dat {
			pinmux = <PINMUX_GPIO129__FUNC_GPIO129>;		//check
			slew-rate = <1>;
			bias-pull-down;
		};
	};
};

&mt6360_pmu {
	mt6360,intr_gpio_num = <24>; /* direct defined GPIO num */
	mt6360,intr_gpio = <&pio 24 0x0>;
	/* 2020/06/30, Modify for LPSD */
	disable_lpsd = <1>;
};

&mt6360_pmic {
	pwr_off_seq = [04 00 02 02];
};

&mt6360_typec {
	mt6360pd,intr_gpio_num = <25>; /* direct defined GPIO num */
	mt6360pd,intr_gpio = <&pio 25 0x0>;
};

//#ifdef OPLUS_FEATURE_CHG_BASIC
/* 2020/09/01, add for mp2762 for svooc */
&lk_charger{
	charger_by_buckboost;
	support_tuv_authentication;
	max_charger_voltage = <9900000>;
};
//#endif

/* USB SWITCH GPIO start */
//#ifdef OPLUS_ARCH_EXTENDS
//#endif
/*
&pio {
	usb_default: usb_default {
	};

	gpio_redriver_c1_init: c1_init {
		pins_cmd_dat {
			pinmux = <PINMUX_GPIO113__FUNC_GPIO113>;
			slew-rate = <1>;
			output-low;
		};
	};

	gpio_redriver_c1_low: c1_low {
		pins_cmd_dat {
			pinmux = <PINMUX_GPIO113__FUNC_GPIO113>;
			slew-rate = <1>;
			output-low;
		};
	};

	gpio_redriver_c1_hiz: c1_highz {
		pins_cmd_dat {
			pinmux = <PINMUX_GPIO113__FUNC_GPIO113>;
			slew-rate= <0>;
			bias-disable;
		};
	};

	gpio_redriver_c1_high: c1_high {
		pins_cmd_dat {
			pinmux = <PINMUX_GPIO113__FUNC_GPIO113>;
			slew-rate = <1>;
			output-high;
		};
	};

	gpio_redriver_c2_init: c2_init {
		pins_cmd_dat {
			pinmux = <PINMUX_GPIO112__FUNC_GPIO112>;
			slew-rate = <1>;
			output-low;
		};
	};

	gpio_redriver_c2_low: c2_low {
		pins_cmd_dat {
			pinmux = <PINMUX_GPIO112__FUNC_GPIO112>;
			slew-rate = <1>;
			output-low;
		};
	};

	gpio_redriver_c2_hiz: c2_highz {
		pins_cmd_dat {
			pinmux = <PINMUX_GPIO112__FUNC_GPIO112>;
			slew-rate= <0>;
			bias-disable;
		};
	};

	gpio_redriver_c2_high: c2_high {
		pins_cmd_dat {
			pinmux = <PINMUX_GPIO112__FUNC_GPIO112>;
			slew-rate = <1>;
			output-high;
		};
	};

	gpio_u3_switch_sel1: u3_sw_sel1 {
		pins_cmd_dat {
			pinmux = <PINMUX_GPIO111__FUNC_GPIO111>;
			slew-rate = <1>;
			output-low;
		};
	};

	gpio_u3_switch_sel2: u3_sw_sel2 {
		pins_cmd_dat {
			pinmux = <PINMUX_GPIO111__FUNC_GPIO111>;
			slew-rate = <1>;
			output-high;
		};
	};

	gpio_u3_switch_enable: u3_sw_en {
	};

	gpio_u3_switch_disable: u3_sw_dis {
	};
};

&usb_c_pinctrl {
	pinctrl-names = "usb_default",
		"redrv_c1_init",
		"redrv_c1_low",
		"redrv_c1_hiz",
		"redrv_c1_high",
		"redrv_c2_init",
		"redrv_c2_low",
		"redrv_c2_hiz",
		"redrv_c2_high",
		"switch_sel1",
		"switch_sel2",
		"switch_enable",
		"switch_disable";

	pinctrl-0 = <&usb_default>;
	pinctrl-1 = <&gpio_redriver_c1_init>;
	pinctrl-2 = <&gpio_redriver_c1_low>;
	pinctrl-3 = <&gpio_redriver_c1_hiz>;
	pinctrl-4 = <&gpio_redriver_c1_high>;
	pinctrl-5 = <&gpio_redriver_c2_init>;
	pinctrl-6 = <&gpio_redriver_c2_low>;
	pinctrl-7 = <&gpio_redriver_c2_hiz>;
	pinctrl-8 = <&gpio_redriver_c2_high>;
	pinctrl-9 = <&gpio_u3_switch_sel1>;
	pinctrl-10 = <&gpio_u3_switch_sel2>;
	pinctrl-11 = <&gpio_u3_switch_enable>;
	pinctrl-12 = <&gpio_u3_switch_disable>;
	status = "okay";

	usb_switch-data {
		en_pin_num = <0>;
		en_pin_val = <0>;
		sel_pin_num = <111>;
		sel_pin_val = <1>;
		c1_pin_num = <113>;
		c1_pin_val = <2>;
		c2_pin_num = <112>;
		c2_pin_val = <1>;
	};
};
*/
/* USB SWITCH GPIO end */

/* GPS GPIO standardization start */
&pio {
	gps_pins_default: gps_default {
	};

	gps_l1_lna_pins_ol: gps_l1_lna@0 {
		pins_cmd_dat {
			pinmux = <PINMUX_GPIO162__FUNC_GPIO162>;
			output-low;
		};
	};
	gps_l1_lna_pins_dsp_ctrl: gps_l1_lna@1 {
		pins_cmd_dat {
			pinmux = <PINMUX_GPIO162__FUNC_GPS_L1_ELNA_EN>;
		};
	};
	gps_l1_lna_pins_oh: gps_l1_lna@2 {
		pins_cmd_dat {
			pinmux = <PINMUX_GPIO162__FUNC_GPIO162>;
			output-high;
		};
	};

	gps_l5_lna_pins_ol: gps_l5_lna@0 {
		pins_cmd_dat {
			pinmux = <PINMUX_GPIO163__FUNC_GPIO163>;
			output-low;
		};
	};
	gps_l5_lna_pins_dsp_ctrl: gps_l5_lna@1 {
		pins_cmd_dat {
			pinmux = <PINMUX_GPIO163__FUNC_GPS_L5_ELNA_EN>;
		};
	};
	gps_l5_lna_pins_oh: gps_l5_lna@2 {
		pins_cmd_dat {
			pinmux = <PINMUX_GPIO163__FUNC_GPIO163>;
			output-high;
		};
	};
};

&gps {
	pinctrl-names = "default",
		"gps_l1_lna_disable",
		"gps_l1_lna_dsp_ctrl",
		"gps_l1_lna_enable",
		"gps_l5_lna_disable",
		"gps_l5_lna_dsp_ctrl",
		"gps_l5_lna_enable";
	pinctrl-0 = <&gps_pins_default>;
	pinctrl-1 = <&gps_l1_lna_pins_ol>;
	pinctrl-2 = <&gps_l1_lna_pins_dsp_ctrl>;
	pinctrl-3 = <&gps_l1_lna_pins_oh>;
	pinctrl-4 = <&gps_l5_lna_pins_ol>;
	pinctrl-5 = <&gps_l5_lna_pins_dsp_ctrl>;
	pinctrl-6 = <&gps_l5_lna_pins_oh>;
	status = "okay";
};
/* GPS GPIO standardization end */

&dsi0 {
	status = "okay";
	#address-cells = <1>;
	#size-cells = <0>;
	panel1@0 {
		compatible = "oplus20131_boe_nt37800_1080p_dsi_cmd";
		reg = <0>;
		pm-enable-gpios = <&pio 41 0>;
		reset-gpios = <&pio 42 0>;
		bias-gpios = <&pio 29 0>;
		ldo3-supply = <&mt_pmic_vmc_ldo_reg>;
		/*pm8008ldo1-supply = <&L1P>;*/
		pinctrl-names = "default";
		port {
			panel_in1: endpoint {
				remote-endpoint = <&dsi_out>;
			};
		};
	};
	panel2@0 {
		compatible = "oplus20131_tianma_nt37701_1080p_dsi_cmd";
		reg = <1>;
		pm-enable-gpios = <&pio 41 0>;
		reset-gpios = <&pio 42 0>;
		bias-gpios = <&pio 29 0>;
		ldo3-supply = <&mt_pmic_vmc_ldo_reg>;
		/*pm8008ldo1-supply = <&L1P>;*/
		pinctrl-names = "default";
		port {
			panel_in2: endpoint {
				remote-endpoint = <&dsi_out>;
			};
		};
	};
	panel3@0 {
		compatible = "oplus20131_tianma_nt37701_32_1080p_dsi_cmd";
		reg = <2>;
		pm-enable-gpios = <&pio 41 0>;
		reset-gpios = <&pio 42 0>;
		bias-gpios = <&pio 29 0>;
		ldo3-supply = <&mt_pmic_vmc_ldo_reg>;
		/*pm8008ldo1-supply = <&L1P>;*/
		pinctrl-names = "default";
		port {
			panel_in3: endpoint {
				remote-endpoint = <&dsi_out>;
			};
		};
	};
	panel4@0 {
		compatible = "oplus20131_samsung_ana6705_1080p_dsi_cmd,lcm";
		reg = <3>;
		pm-enable-gpios = <&pio 41 0>;
		reset-gpios = <&pio 42 0>;
		bias-gpios = <&pio 29 0>;
		ldo3-supply = <&mt_pmic_vmc_ldo_reg>;
		pinctrl-names = "default";
		port {
			panel_in4: endpoint {
				remote-endpoint = <&dsi_out>;
			};
		};
	};

	ports {
		port {
			dsi_out: endpoint {
				remote-endpoint = <&panel_in1>;
			};
		};
	};
};

/*#ifdef OPLUS_BUG_STABILITY*/
&i2c9 {
        fan53870@35 {
                compatible = "fan53870";
                reg = <0x35>;
                ldo1_min_vol = <800000>;  /*uV*/
                ldo1_max_vol = <1504000>;
                ldo1_step_vol = <8000>;
        };
        wl2868c@2f {
                compatible = "wl2868c-i2c";
                reg = <0x2f>;
                id_reg = <0x00>;
                id_val = <0x82>;
                vin1_vol = <800000>;
                vin2_vol = <1504000>;
                en-gpios = <&pio 29 1>;
        };
};
/*#endif*/

/* CAMERA specify sensor */
&kd_camera_hw1 {
	cam2_enable_sensor = "imx350_mipi_raw imx386_mipi_mono imx319_mipi_raw";
};
/* CAMERA specify sensor end */

//#ifdef OPLUS_FEATURE_TP_BASIC
&i2c0 {

	synaptics20131@4B {
		compatible = "synaptics-s3908";
		reg = <0x4B>;
		chip-name = "S3908";

		/* Interrupt && Irq-gpio */
		interrupt-parent = <&pio>;
		interrupts = <21 0x2008>;

		/* Power Config */
		vdd_2v8-supply  = <&mt_pmic_vtp_ldo_reg>;
		vdd_2v8_volt = <3000000>;
		/* Other HW Resource */

		irq-gpio = <&pio 21 0x2008>;
		reset-gpio = <&pio 20 0x1>;
		pinctrl-names = "default";
		pinctrl-0 = <&ctp_ts_int_active &ctp_ts_reset_suspend>;

		touchpanel,max-num-support = <10>;
                touchpanel,tx-rx-num = <16 36>;
                touchpanel,panel-coords = <5400 12000>;
                touchpanel,display-coords = <1080 2400>;
                touchpanel,touchmajor-limit = <160 270>;
		//touchpanel,elimination-range = <20 200 200>;
                touchpanel,int-mode = <1>; /*0: interrupt and disable, 1:interrupt and not disable*/
		touchpanel,smooth-level = <0 1 2 3 8 10>;
		touchpanel,sensitive-level = <0 88 70 64 45 10>;

		vid_len = <2>;
		tp_type = <3>; /*type:8 BOE*/
		platform_support_project = <20131 20133 20255 20257
                				20131 20133 20255 20257>;
		platform_support_project_dir = <20131 20131 20131 20131
                				20131 20131 20131 20131>;
		platform_support_project_commandline = "oppo20131_boe_nt37800_1080p_dsi_cmd","oppo20131_boe_nt37800_1080p_dsi_cmd",
                					"oppo20131_boe_nt37800_1080p_dsi_cmd","oppo20131_boe_nt37800_1080p_dsi_cmd",
							"oppo20131_tianma_nt37701","oppo20131_tianma_nt37701",
                                                        "oppo20131_tianma_nt37701","oppo20131_tianma_nt37701";

		prevention,dead_area_width = <30 30>;
		prevention,makeup_cnt_weight = <4 1 2 2 1>;
		prevention,large_judge_para = <30 8 8>;
		prevention,large_corner_judge_para = <30 5 5 80 80 0>;

		prevention,curved_large_area_width = <500 500 400 3 3>;
		prevention,large_curved_long_judge_para = <7 180 30 15 15 7 4 7 5 3 3>;
		prevention,large_curved_short_judge_para = <6 180 30 0 15 7 4 7 5 2 3>;
		prevention,grip_large_detect_time = <175>;
		prevention,grip_down_delta_time = <150>;
		prevention,curved_screen;

		prevention,condition_judge_para = <40 10>;
		prevention,condition_area_width = <0 0 80 80>;
		prevention,large_area_width = <0 0>;
		prevention,large_corner_width = <0 0 0>;
		prevention,eli_area_width = <0 0 0 0 0 0>;
		prevention,grip_disable_level = <6>;

		/* SW Support Feature Control */
		health_monitor_v2_support;
		black_gesture_support;
		charger_pump_support;
		lcd_tp_refresh_support;
		fw_update_app_support;
		smart_gesture_support;
		game_switch_support;
		report_flow_unlock_support;
		kernel_grip_support;
		fingerprint_underscreen_support;
		headset_pump_support;
		pressure_report_support;
		irq_need_dev_resume_ok;
		touchpanel,single-optimized-time = <8>;
		/*
		 *Virtual Key Config:
		 *1:touchpanel,button-type: <virtualkey_type  supportted_button-map>
		 *virtualkey_type:
		 *Type 1: using board_properties
		 *Type 2: using same IC (button zone&& touch zone are seprate)
		 *Type 3: using diffrent IC (button zone&& touch zone are seprate)
		 *Type 4: No need of virtual key process
		 *supportted_button-map:select|menu|home|back
		 *
		 *2:touchpanel,button-map
		 *type (X1,Y1)(X2,Y2)(X3,Y3)(Width_X,Hight_Y)--Only when button-type is 0
		 */
		touchpanel,button-type = <4>;
		touchpanel.button-TRx = <0 0>;

		S3908 {
			report_rate_default = <90>;
			report_rate_game_value = <2>;
		};
	};

	s6sy792_20131@48 {
		compatible = "sec-s6sy792";
		reg = <0x48>;
		chip-name = "S6SY792";

                /* Interrupt && Irq-gpio */
                interrupt-parent = <&pio>;
                interrupts = <21 0x2008>;

                /* Power Config */
                vdd_2v8-supply  = <&mt_pmic_vtp_ldo_reg>;
                vdd_2v8_volt = <3000000>;
                /* Other HW Resource */

                irq-gpio = <&pio 21 0x2008>;
                reset-gpio = <&pio 20 0x1>;
                pinctrl-names = "default";
                pinctrl-0 = <&ctp_ts_int_active &ctp_ts_reset_suspend>;

		touchpanel,max-num-support = <10>;
                touchpanel,tx-rx-num = <16 36>;
                touchpanel,panel-coords = <5400 12000>;
                touchpanel,display-coords = <1080 2400>;
                touchpanel,touchmajor-limit = <160 270>;
                //touchpanel,elimination-range = <20 200 200>;
		touchpanel,smooth-level = <255 0 2 4 5 6>;
		touchpanel,smooth-level-charging = <255 9 10 10 11 11>;
		touchpanel,sensitive-level = <255 20 15 10 5 1>;

                vid_len = <2>;
                tp_type = <8>; /*type:8 SAMSUNG*/
                platform_support_project = <20131 20133 20255 20257>;
        	platform_support_project_dir = <20131 20131 20131 20131>;
                platform_support_project_commandline = "oppo20131_samsung_ana6705_1080p_dsi_cmd","oppo20131_samsung_ana6705_1080p_dsi_cmd","oppo20131_samsung_ana6705_1080p_dsi_cmd","oppo20131_samsung_ana6705_1080p_dsi_cmd";

		prevention,dead_area_width = <30 30>;
		prevention,makeup_cnt_weight = <4 1 2 2 1>;
		prevention,large_judge_para = <30 8 8>;
		prevention,large_corner_judge_para = <30 5 5 80 80 0>;

		prevention,curved_large_area_width = <500 500 400 3 3>;
		prevention,large_curved_long_judge_para = <6 180 30 15 15 7 4 7 5 3 3>;
		prevention,large_curved_short_judge_para = <6 180 30 0 15 7 4 7 5 2 3>;
		prevention,grip_large_detect_time = <175>;
		prevention,grip_down_delta_time = <125>;
		prevention,curved_screen;

		prevention,condition_judge_para = <40 10>;
		prevention,condition_area_width = <0 0 80 80>;
		prevention,large_area_width = <0 0>;
		prevention,large_corner_width = <0 0 0>;
		prevention,eli_area_width = <0 0 0 0 0 0>;
		prevention,grip_disable_level = <6>;

		/* SW Support Feature Control */
		health_monitor_v2_support;
		black_gesture_support;
		charger_pump_support;
		fw_update_app_support;
		smart_gesture_support;
		game_switch_support;
		kernel_grip_support;
		fingerprint_underscreen_support;
		headset_pump_support;
		pressure_report_support;
		irq_need_dev_resume_ok;
		sec_kernel_grip_para = <21000>;
		auto_test_need_cal_support;
		touchpanel,single-optimized-time = <8>;

                /*
                 *Virtual Key Config:
                 *1:touchpanel,button-type: <virtualkey_type  supportted_button-map>
                 *virtualkey_type:
                 *Type 1: using board_properties
                 *Type 2: using same IC (button zone&& touch zone are seprate)
                 *Type 3: using diffrent IC (button zone&& touch zone are seprate)
                 *Type 4: No need of virtual key process
                 *supportted_button-map:select|menu|home|back
                 *
                 *2:touchpanel,button-map
                 *type (X1,Y1)(X2,Y2)(X3,Y3)(Width_X,Hight_Y)--Only when button-type is 0
                 */
                touchpanel,button-type = <4>;
                touchpanel.button-TRx = <0 0>;
	};
};

&pio {
	ctp_pins_default: eintdefault {
	};
	ctp_ts_int_active: int_active {
		pins_cmd_dat {
			pinmux = <PINMUX_GPIO21__FUNC_GPIO21>;
			slew-rate = <0>;
			bias-pull-up;
		};
	};
	ctp_ts_reset_active: reset_active {
		pins_cmd_dat {
			pinmux = <PINMUX_GPIO20__FUNC_GPIO20>;
			slew-rate = <1>;
			output-high;
		};
	};
	ctp_ts_int_suspend: int_suspend {
		pins_cmd_dat {
			pinmux = <PINMUX_GPIO21__FUNC_GPIO21>;
			slew-rate = <1>;
			output-low;
		};
	};
	ctp_ts_reset_suspend: reset_suspend {
		pins_cmd_dat {
			pinmux = <PINMUX_GPIO20__FUNC_GPIO20>;
			slew-rate = <1>;
			output-low;
		};
	};
};
//#endif OPLUS_FEATURE_TP_BASIC
#include "mediatek/cust_mt6889_camera_20131.dtsi"
#include <oplus6889_20255_v1/cust.dtsi>
/*End of this file, DO NOT ADD ANYTHING HERE*/
